AUTOSAR XML (schema 4-2-2)
package /Components
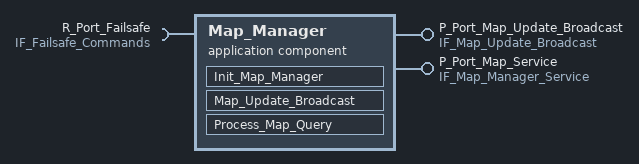
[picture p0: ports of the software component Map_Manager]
  application sw component type Map_Manager
    provide port P_Port_Map_Update_Broadcast: provided-interface=IF_Map_Update_Broadcast
    provide port P_Port_Map_Service: provided-interface=IF_Map_Manager_Service
    require port R_Port_Failsafe: required-interface=IF_Failsafe_Commands
    behavior Map_Manager_InternalBehavior
      init event Map_Manager_Init: start-on-event=Init_Map_Manager
      operation invoked event Map_Request_Invoked: start-on-event=Process_Map_Query
      runnable Init_Map_Manager
        parameter access InitParamAccess_Map_Version: accessed-parameter=P_Port_Map_Update_Broadcast.Map_Version
      runnable Map_Update_Broadcast: minimum-start-interval=500
        data-read-access:
          access Read_Map_Tile_Update: accessed-variable={autosar-variable-in-impl-datatype={port-prototype=P_Port_Map_Update_Broadcast, target-data-prototype=Map_Tile_Update_Impl}, autosar-variable=P_Port_Map_Update_Broadcast.Map_Tile_Update}
          access Read_Map_Version: accessed-variable={autosar-variable-in-impl-datatype={port-prototype=P_Port_Map_Update_Broadcast, target-data-prototype=Map_Version_Impl}, autosar-variable=P_Port_Map_Update_Broadcast.Map_Version}
        data-send-points:
          access Send_Map_Tile_Update: accessed-variable={autosar-variable-in-impl-datatype={port-prototype=P_Port_Map_Update_Broadcast, target-data-prototype=Map_Tile_Update_Impl}, autosar-variable=P_Port_Map_Update_Broadcast.Map_Tile_Update}
          access Send_Map_Version: accessed-variable={autosar-variable-in-impl-datatype={port-prototype=P_Port_Map_Update_Broadcast, target-data-prototype=Map_Version_Impl}, autosar-variable=P_Port_Map_Update_Broadcast.Map_Version}
      runnable Process_Map_Query: minimum-start-interval=1, can-be-invoked-concurrently=true
